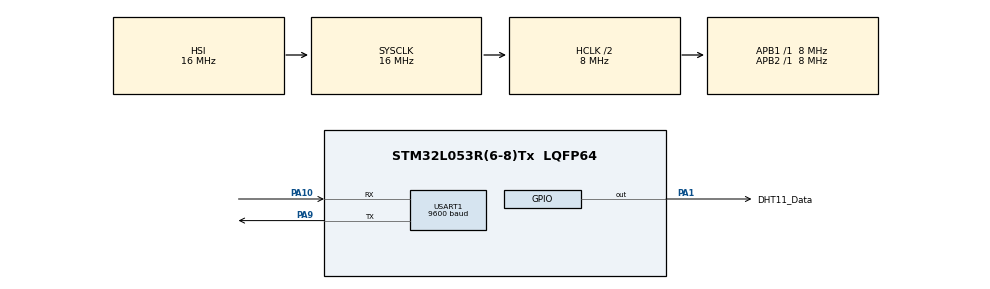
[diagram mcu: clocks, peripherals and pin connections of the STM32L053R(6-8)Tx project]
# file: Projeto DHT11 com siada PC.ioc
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Mcu.Family=STM32L0
Mcu.Name=STM32L053R(6-8)Tx
Mcu.Package=LQFP64
PA1.GPIO_Label=DHT11_Data
PA1.Signal=GPIO_Output
PA10.Mode=Asynchronous
PA10.Signal=USART1_RX
PA9.Mode=Asynchronous
PA9.Signal=USART1_TX
ProjectManager.HeapSize=0x200
ProjectManager.StackSize=0x400
ProjectManager.TargetToolchain=STM32CubeIDE
RCC.AHBCLKDivider=RCC_SYSCLK_DIV2
RCC.AHBFreq_Value=8000000
RCC.APB1Freq_Value=8000000
RCC.APB1TimFreq_Value=8000000
RCC.APB2Freq_Value=8000000
RCC.APB2TimFreq_Value=8000000
RCC.HCLKFreq_Value=8000000
RCC.HSE_VALUE=8000000
RCC.HSI16_VALUE=16000000
RCC.HSI48_VALUE=48000000
RCC.HSI_VALUE=16000000
RCC.MSI_VALUE=2097000
RCC.SYSCLKFreq_VALUE=16000000
RCC.SYSCLKSource=RCC_SYSCLKSOURCE_HSI
RCC.VCOOutputFreq_Value=48000000
TIM6.Period=0xFFFF-1
TIM6.Prescaler=8-1
USART1.BaudRate=9600
USART1.VirtualMode-Asynchronous=VM_ASYNC
VP_TIM6_VS_ClockSourceINT.Mode=Enable_Timer
board=NUCLEO-L053R8

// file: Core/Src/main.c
/* USER CODE BEGIN Header */
/**
  ******************************************************************************
  * @file           : main.c
  * @brief          : Main program body
  ******************************************************************************
  * @attention
  *
  * Copyright (c) 2025 STMicroelectronics.
  * All rights reserved.
  *
  * This software is licensed under terms that can be found in the LICENSE file
  * in the root directory of this software component.
  * If no LICENSE file comes with this software, it is provided AS-IS.
  *
  ******************************************************************************
  */
/* USER CODE END Header */
#include "main.h"

/* USER CODE BEGIN Includes */
#include <stdio.h>
#include <string.h>
/* USER CODE END Includes */

/* USER CODE BEGIN PD */
#define DHT11_PORT GPIOA
#define DHT11_PIN GPIO_PIN_1

/* USER CODE END PD */

TIM_HandleTypeDef htim6;

UART_HandleTypeDef huart1;

/* USER CODE BEGIN PV */
uint16_t SUM, RH, TEMP;
float Temperature = 0, Humidity = 0;

uint8_t Rh_byte1, Rh_byte2, Tmp_byte1, Tmp_byte2, Presence = 0;
/* USER CODE END PV */

void SystemClock_Config(void);
static void MX_GPIO_Init(void);
static void MX_TIM6_Init(void);
static void MX_USART1_UART_Init(void);
/* USER CODE BEGIN PFP */
void SendValues(float Temp, float Rh);
void Delay_MicroSeconds(uint16_t time);
void Set_PinOutput(GPIO_TypeDef *GPIOx, uint16_t GPIO_Pin);
void Set_PinInput(GPIO_TypeDef *GPIOx, uint16_t GPIO_Pin);

/*---------------------------------- DHT11 -------------------------------------*/

void DHT11_Start(void){
	Set_PinInput(DHT11_PORT, DHT11_PIN);

	HAL_GPIO_WritePin(DHT11_PORT, DHT11_PIN, GPIO_PIN_RESET);
	HAL_Delay(18);
	HAL_GPIO_WritePin(DHT11_PORT, DHT11_PIN, GPIO_PIN_SET);
	Delay_MicroSeconds(30);

	Set_PinOutput(DHT11_PORT, DHT11_PIN);
}

uint8_t DHT11_CheckResponse(void){
	uint8_t Response;
	Delay_MicroSeconds(40);

	if (!HAL_GPIO_ReadPin(DHT11_PORT, DHT11_PIN)){
		Delay_MicroSeconds(80);
		if ((HAL_GPIO_ReadPin(DHT11_PORT, DHT11_PIN))) Response = 1;
		else Response = -1; // 255
	}

	while((HAL_GPIO_ReadPin(DHT11_PORT, DHT11_PIN)));
	return Response;
}

uint8_t DHT11_Read(void){
	int response = 0, i;

	for(i = 0; i < 8; i++){
		while(!(HAL_GPIO_ReadPin(DHT11_PORT, DHT11_PIN)));
		Delay_MicroSeconds(40);

		if (!(HAL_GPIO_ReadPin(DHT11_PORT, DHT11_PIN))) response &= ~(1 << (7 - i));
		else response |= ~(1 <<(7 - i));

		while((HAL_GPIO_ReadPin(DHT11_PORT, DHT11_PIN)));
	}

	return response;
}

/* USER CODE END PFP */

int main(void)
{

  /* MCU Configuration--------------------------------------------------------*/

  /* Reset of all peripherals, Initializes the Flash interface and the Systick. */
  HAL_Init();

  /* Configure the system clock */
  SystemClock_Config();

  /* Initialize all configured peripherals */
  MX_GPIO_Init();
  MX_TIM6_Init();
  MX_USART1_UART_Init();
  /* USER CODE BEGIN 2 */
  HAL_TIM_Base_Start(&htim6);
  DHT11_Start();
  /* USER CODE END 2 */

  /* Infinite loop */
  /* USER CODE BEGIN WHILE */
  while (1) {
	  Presence = DHT11_CheckResponse();
	  Rh_byte1 = DHT11_Read();
	  Rh_byte2 = DHT11_Read();

	  Tmp_byte1 = DHT11_Read();
	  Tmp_byte2 = DHT11_Read();

	  SUM = DHT11_Read();

	  TEMP = Tmp_byte1;
	  RH = Rh_byte1;

	  Temperature = (float) TEMP;
	  Humidity = (float) RH;

	  SendValues(Temperature, Humidity);
	  HAL_Delay(1000);
    /* USER CODE END WHILE */

  }
}

void SystemClock_Config(void)
{
  RCC_OscInitTypeDef RCC_OscInitStruct = {0};
  RCC_ClkInitTypeDef RCC_ClkInitStruct = {0};
  RCC_PeriphCLKInitTypeDef PeriphClkInit = {0};

  /** Configure the main internal regulator output voltage
  */
  __HAL_PWR_VOLTAGESCALING_CONFIG(PWR_REGULATOR_VOLTAGE_SCALE1);

  /** Initializes the RCC Oscillators according to the specified parameters
  * in the RCC_OscInitTypeDef structure.
  */
  RCC_OscInitStruct.OscillatorType = RCC_OSCILLATORTYPE_HSI;
  RCC_OscInitStruct.HSIState = RCC_HSI_ON;
  RCC_OscInitStruct.HSICalibrationValue = RCC_HSICALIBRATION_DEFAULT;
  RCC_OscInitStruct.PLL.PLLState = RCC_PLL_NONE;
  if (HAL_RCC_OscConfig(&RCC_OscInitStruct) != HAL_OK)
  {
    Error_Handler();
  }

  /** Initializes the CPU, AHB and APB buses clocks
  */
  RCC_ClkInitStruct.ClockType = RCC_CLOCKTYPE_HCLK|RCC_CLOCKTYPE_SYSCLK
                              |RCC_CLOCKTYPE_PCLK1|RCC_CLOCKTYPE_PCLK2;
  RCC_ClkInitStruct.SYSCLKSource = RCC_SYSCLKSOURCE_HSI;
  RCC_ClkInitStruct.AHBCLKDivider = RCC_SYSCLK_DIV2;
  RCC_ClkInitStruct.APB1CLKDivider = RCC_HCLK_DIV1;
  RCC_ClkInitStruct.APB2CLKDivider = RCC_HCLK_DIV1;

  if (HAL_RCC_ClockConfig(&RCC_ClkInitStruct, FLASH_LATENCY_0) != HAL_OK)
  {
    Error_Handler();
  }
  PeriphClkInit.PeriphClockSelection = RCC_PERIPHCLK_USART1;
  PeriphClkInit.Usart1ClockSelection = RCC_USART1CLKSOURCE_PCLK2;
  if (HAL_RCCEx_PeriphCLKConfig(&PeriphClkInit) != HAL_OK)
  {
    Error_Handler();
  }
}

static void MX_TIM6_Init(void)
{

  TIM_MasterConfigTypeDef sMasterConfig = {0};

  htim6.Instance = TIM6;
  htim6.Init.Prescaler = 8-1;
  htim6.Init.CounterMode = TIM_COUNTERMODE_UP;
  htim6.Init.Period = 0xFFFF-1;
  htim6.Init.AutoReloadPreload = TIM_AUTORELOAD_PRELOAD_DISABLE;
  if (HAL_TIM_Base_Init(&htim6) != HAL_OK)
  {
    Error_Handler();
  }
  sMasterConfig.MasterOutputTrigger = TIM_TRGO_RESET;
  sMasterConfig.MasterSlaveMode = TIM_MASTERSLAVEMODE_DISABLE;
  if (HAL_TIMEx_MasterConfigSynchronization(&htim6, &sMasterConfig) != HAL_OK)
  {
    Error_Handler();
  }

}

static void MX_USART1_UART_Init(void)
{

  huart1.Instance = USART1;
  huart1.Init.BaudRate = 9600;
  huart1.Init.WordLength = UART_WORDLENGTH_8B;
  huart1.Init.StopBits = UART_STOPBITS_1;
  huart1.Init.Parity = UART_PARITY_NONE;
  huart1.Init.Mode = UART_MODE_TX_RX;
  huart1.Init.HwFlowCtl = UART_HWCONTROL_NONE;
  huart1.Init.OverSampling = UART_OVERSAMPLING_16;
  huart1.Init.OneBitSampling = UART_ONE_BIT_SAMPLE_DISABLE;
  huart1.AdvancedInit.AdvFeatureInit = UART_ADVFEATURE_NO_INIT;
  if (HAL_UART_Init(&huart1) != HAL_OK)
  {
    Error_Handler();
  }

}

static void MX_GPIO_Init(void)
{
  GPIO_InitTypeDef GPIO_InitStruct = {0};

  /* GPIO Ports Clock Enable */
  __HAL_RCC_GPIOA_CLK_ENABLE();

  /*Configure GPIO pin Output Level */
  HAL_GPIO_WritePin(DHT11_Data_GPIO_Port, DHT11_Data_Pin, GPIO_PIN_RESET);

  /*Configure GPIO pin : DHT11_Data_Pin */
  GPIO_InitStruct.Pin = DHT11_Data_Pin;
  GPIO_InitStruct.Mode = GPIO_MODE_OUTPUT_PP;
  GPIO_InitStruct.Pull = GPIO_NOPULL;
  GPIO_InitStruct.Speed = GPIO_SPEED_FREQ_LOW;
  HAL_GPIO_Init(DHT11_Data_GPIO_Port, &GPIO_InitStruct);

}

/* USER CODE BEGIN 4 */
void Delay_MicroSeconds(uint16_t time){
	__HAL_TIM_SET_COUNTER(&htim6, 0);
	while((__HAL_TIM_GET_COUNTER(&htim6)) < time);
}

void Set_PinOutput(GPIO_TypeDef *GPIOx, uint16_t GPIO_Pin){
	GPIO_InitTypeDef GPIO_InitStruct = {0};
	GPIO_InitStruct.Pin = GPIO_Pin;
	GPIO_InitStruct.Mode = GPIO_MODE_OUTPUT_PP;
	GPIO_InitStruct.Pull = GPIO_NOPULL;
	HAL_GPIO_Init(DHT11_PORT, &GPIO_InitStruct);
}

void Set_PinInput(GPIO_TypeDef *GPIOx, uint16_t GPIO_Pin){
	GPIO_InitTypeDef GPIO_InitStruct = {0};
	GPIO_InitStruct.Pin = GPIO_Pin;
	GPIO_InitStruct.Mode = GPIO_MODE_INPUT;
	GPIO_InitStruct.Pull = GPIO_NOPULL;
	HAL_GPIO_Init(DHT11_PORT, &GPIO_InitStruct);
}

void SendValues(float Temp, float Rh){
	char buffer[30] = {0};

	sprintf(buffer, "TEMP: %.2f C\nRH: %.2f %%", Temp, Rh);
	HAL_UART_Transmit(&huart1, (uint8_t *) buffer, strlen(buffer), 100);
}

/* USER CODE END 4 */

void Error_Handler(void)
{
  __disable_irq();
  while (1)
  {
  }
}
